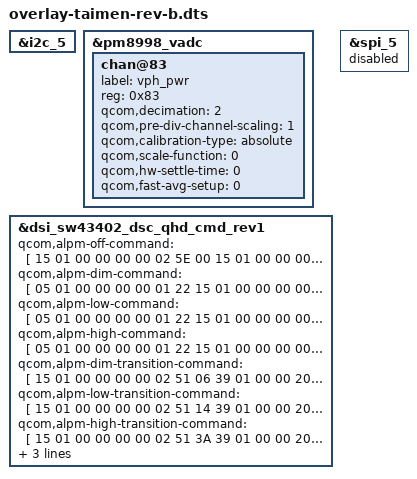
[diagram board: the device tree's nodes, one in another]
/* Copyright (c) 2017, The Linux Foundation. All rights reserved.
 *
 * This program is free software; you can redistribute it and/or modify
 * it under the terms of the GNU General Public License version 2 and
 * only version 2 as published by the Free Software Foundation.
 *
 * This program is distributed in the hope that it will be useful,
 * but WITHOUT ANY WARRANTY; without even the implied warranty of
 * MERCHANTABILITY or FITNESS FOR A PARTICULAR PURPOSE.  See the
 * GNU General Public License for more details.
 */

/dts-v1/;
/plugin/;

#include "msm8998-taimen.dtsi"

&i2c_5 {
	status = "ok";
};

&pm8998_vadc {
	chan@83 {
		label = "vph_pwr";
		reg = <0x83>;
		qcom,decimation = <2>;
		qcom,pre-div-channel-scaling = <1>;
		qcom,calibration-type = "absolute";
		qcom,scale-function = <0>;
		qcom,hw-settle-time = <0>;
		qcom,fast-avg-setup = <0>;
	};
};

&dsi_sw43402_dsc_qhd_cmd_rev1 {
	qcom,alpm-off-command = [
		15 01 00 00 00 00 02 5E 00
		15 01 00 00 00 00 02 51 01
		05 01 00 00 12 00 01 22
		05 01 00 00 00 00 01 38
		39 01 00 00 00 00 03 E2 20 0D
		05 01 00 00 40 00 01 28
		05 01 00 00 00 00 01 13
		05 01 00 00 00 00 01 29
	];
	qcom,alpm-dim-command = [
		05 01 00 00 00 00 01 22
		15 01 00 00 00 00 02 E0 1A
		39 01 00 00 34 00 03 E2 20 03
		39 01 00 00 00 00 03 E4 30 44
		39 01 00 00 00 00 07 E5 04 06 03 03 56 61
		39 01 00 00 00 00 09 E7 00 0D 76 23 00 00 0D 44
		05 01 00 00 00 00 01 39
		15 01 00 00 00 00 02 51 06
		05 01 00 00 54 00 01 13
		15 01 00 00 00 00 02 5E 10
	];
	qcom,alpm-low-command = [
		05 01 00 00 00 00 01 22
		15 01 00 00 00 00 02 E0 1A
		39 01 00 00 34 00 03 E2 20 03
		39 01 00 00 00 00 03 E4 30 44
		39 01 00 00 00 00 07 E5 04 06 03 03 56 61
		39 01 00 00 00 00 09 E7 00 0D 76 23 00 00 0D 44
		05 01 00 00 00 00 01 39
		15 01 00 00 00 00 02 51 14
		05 01 00 00 54 00 01 13
		15 01 00 00 00 00 02 5E 10
	];
	qcom,alpm-high-command = [
		05 01 00 00 00 00 01 22
		15 01 00 00 00 00 02 E0 1A
		39 01 00 00 34 00 03 E2 20 03
		39 01 00 00 00 00 03 E4 30 04
		39 01 00 00 00 00 07 E5 04 06 03 03 56 61
		39 01 00 00 00 00 09 E7 00 0D 76 23 00 00 0D 44
		05 01 00 00 00 00 01 39
		15 01 00 00 00 00 02 51 3A
		05 01 00 00 54 00 01 13
		15 01 00 00 00 00 02 5E 10
	];
	qcom,alpm-dim-transition-command = [
		15 01 00 00 00 00 02 51 06
		39 01 00 00 20 00 03 E4 30 44
	];
	qcom,alpm-low-transition-command = [
		15 01 00 00 00 00 02 51 14
		39 01 00 00 20 00 03 E4 30 44
	];
	qcom,alpm-high-transition-command = [
		15 01 00 00 00 00 02 51 3A
		39 01 00 00 20 00 03 E4 30 04
	];
	qcom,mdss-dsi-bl-off-level = <1>;
	qcom,alpm-dim-threshold = <26>;
	qcom,alpm-bl-threshold = <43>;

};

&spi_5 {
	status = "disabled";
};
